AUTOSAR XML (schema 4-2-2)
package /Components
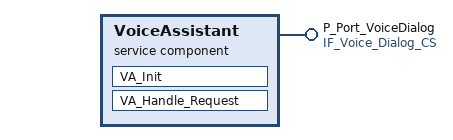
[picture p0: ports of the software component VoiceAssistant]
  service sw component type VoiceAssistant
    provide port P_Port_VoiceDialog: provided-interface=IF_Voice_Dialog_CS
    behavior VoiceAssistant_InternalBehavior
      init event VA_Init_Event: start-on-event=VA_Init
      operation invoked event VA_Operation_Invoked: start-on-event=VA_Handle_Request, operation=P_Port_VoiceDialog.Process_Utterance
      runnable VA_Init
        data-send-points:
          access VA_Send_Init_Status
        parameter access PA_Load_Init_Config: accessed-parameter=P_Port_VoiceDialog.IC_Frame
        sync call SCP_Init_NoOp: operation=R_Port_Internal.Start_Session, timeout=300
      runnable VA_Handle_Request: minimum-start-interval=1, can-be-invoked-concurrently=true
        data-send-points:
          access VA_Send_Dialog_Response
        parameter access PA_Read_Request_Timestamp: accessed-parameter=P_Port_VoiceDialog.Timestamp
        sync call SCP_Process_Utterance: operation=R_Port_Internal.Process_Utterance, timeout=300
